# ETHCAT register map
Registers from a debugger description file.
Registers are 8-bit, read-only, no defined reset value unless marked. A register's access mark holds for its fields unless they carry their own. Addresses are absolute; registers are grouped by the start of their names; lines under a group give offsets from that group; [hi:lo] are bit positions; {n}, {i} and the like mark numbered series; 'fields as' and 'values as' point back to an identical list; <NAME> marks a mode.

## SFR
0x44010000 TYPE
0x44010001 REVISION
  [7:0] REV
0x44010002 BUILD 16-bit
0x44010004 FMMU_NUM
  [7:0] NUMFMMU
0x44010006 RAM_SIZE
  [7:0] RAMSIZE
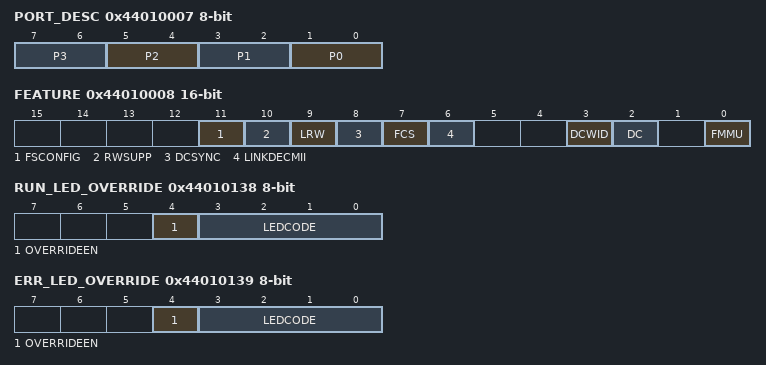
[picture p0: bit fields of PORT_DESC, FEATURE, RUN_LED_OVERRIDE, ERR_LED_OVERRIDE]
0x44010007 PORT_DESC
  [2n+1:2n] P{n} (n=0..3)
0x44010008 FEATURE 16-bit
  [11] FSCONFIG, [10] RWSUPP, [9] LRW, [8] DCSYNC, [7] FCS, [6] LINKDECMII, [3] DCWID, [2] DC, [0] FMMU
0x44010108 PHYSICAL_RW_OFFSET 16-bit
  [15:0] RWOFFSET
0x44010138 RUN_LED_OVERRIDE access not given
  [4] OVERRIDEEN, [3:0] LEDCODE
0x44010139 ERR_LED_OVERRIDE access not given
  [4] OVERRIDEEN, [3:0] LEDCODE
0x44010152 EXT_PDI_CONFIG 16-bit
  [1:0] DATABUSWID
0x44010400 WD_DIVIDE 16-bit
  [15:0] WDDIV
0x44010440 WDS_DATA 16-bit
  [0] WDSTAPD
0x44010E00 PRODUCT_ID 64-bit
  [63:0] PROID
0x44010E08 VENDOR_ID 64-bit
  [31:0] VENDORID

## SYNC
0x44010005 SYNC_MANAGER
  [7:0] NUMSYNC
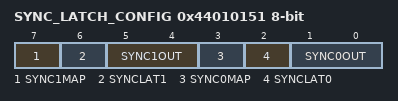
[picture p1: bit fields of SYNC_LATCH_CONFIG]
0x44010151 SYNC_LATCH_CONFIG
  [7] SYNC1MAP, [6] SYNCLAT1, [5:4] SYNC1OUT, [3] SYNC0MAP, [2] SYNCLAT0, [1:0] SYNC0OUT

## STATION
0x44010010 STATION_ADR 16-bit access not given
  [15:0] NODADDR
0x44010012 STATION_ALIAS 16-bit
  [15:0] NODALIADDR

## WR
0x44010020 WR_REG_ENABLE
  [0] ENABLE
0x44010021 WR_REG_PROTECT
  [0] PROTECT

## ESC
0x44010030 ESC_WR_ENABLE
  [0] ENABLE
0x44010031 ESC_WR_PROTECT
  [0] PROTECT
0x44010040 ESC_RESET_ECAT
  [7:0] RESET_ECAT
0x44010041 ESC_RESET_PDI access not given
  [7:0] RESET_PDI
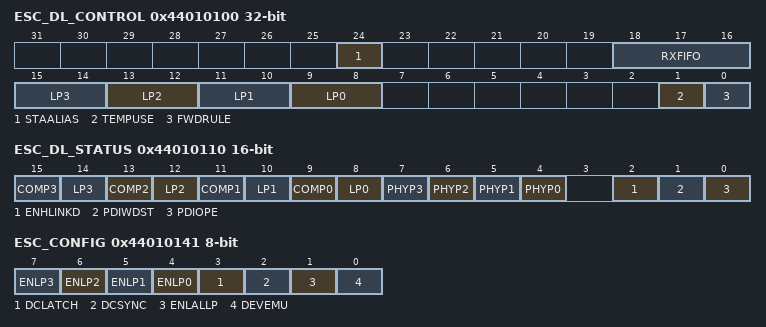
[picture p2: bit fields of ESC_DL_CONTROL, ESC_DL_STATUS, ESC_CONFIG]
0x44010100 ESC_DL_CONTROL 32-bit
  [24] STAALIAS, [18:16] RXFIFO, [2n+9:2n+8] LP{n} (n=0..3), [1] TEMPUSE, [0] FWDRULE
0x44010110 ESC_DL_STATUS 16-bit
  [2n+9] COMP{n} (n=0..3), [2n+8] LP{n} (n=0..3), [n+4] PHYP{n} (n=0..3), [2] ENHLINKD, [1] PDIWDST, [0] PDIOPE
0x44010141 ESC_CONFIG
  [n+4] ENLP{n} (n=0..3), [3] DCLATCH, [2] DCSYNC, [1] ENLALLP, [0] DEVEMU

## AL
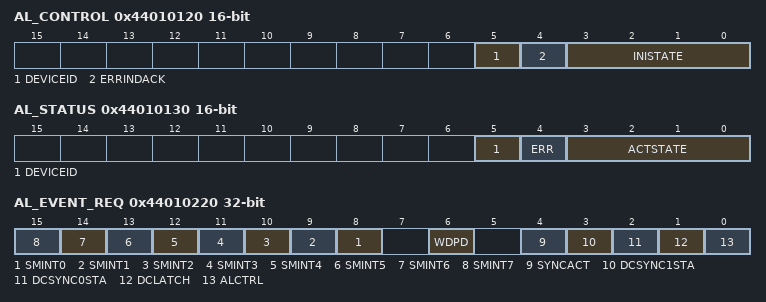
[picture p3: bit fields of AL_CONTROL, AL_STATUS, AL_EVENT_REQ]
0x44010120 AL_CONTROL 16-bit
  [5] DEVICEID, [4] ERRINDACK, [3:0] INISTATE
0x44010130 AL_STATUS 16-bit access not given
  [5] DEVICEID, [4] ERR, [3:0] ACTSTATE
0x44010134 AL_STATUS_CODE 16-bit access not given
  [15:0] STATUSCODE
0x44010204 AL_EVENT_MASK 32-bit access not given
  [31:0] ALEVMASK
0x44010220 AL_EVENT_REQ 32-bit
  [n+8] SMINT{n} (n=0..7), [6] WDPD, [4] SYNCACT, [3] DCSYNC1STA, [2] DCSYNC0STA, [1] DCLATCH, [0] ALCTRL

## PDI
0x44010140 PDI_CONTROL
  [7:0] PDI
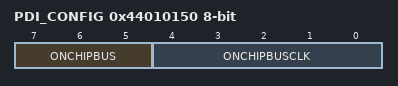
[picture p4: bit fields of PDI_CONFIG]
0x44010150 PDI_CONFIG
  [7:5] ONCHIPBUS, [4:0] ONCHIPBUSCLK
0x4401030D PDI_ERR_COUNT
  [7:0] PDIERRCNT

## ECAT
0x44010200 ECAT_EVENT_MASK 16-bit
  [15:0] ECATEVMASK
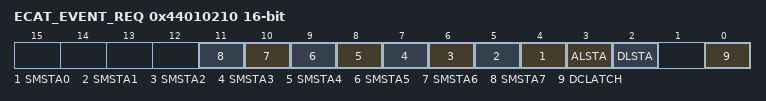
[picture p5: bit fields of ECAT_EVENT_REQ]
0x44010210 ECAT_EVENT_REQ 16-bit
  [n+4] SMSTA{n} (n=0..7), [3] ALSTA, [2] DLSTA, [0] DCLATCH
0x4401030C ECAT_PROC_ERR_COUNT
  [7:0] EPUERRCNT

## RX
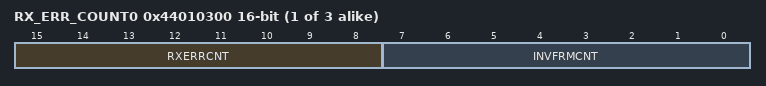
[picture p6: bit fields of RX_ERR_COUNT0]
{0x44010300+2i} RX_ERR_COUNT{i} 16-bit (i=0..2)
  [15:8] RXERRCNT, [7:0] INVFRMCNT

## FWD
{0x44010308+i} FWD_RX_ERR_COUNT{i} (i=0..2)
  [7:0] FWDERRCNT

## LOST
{0x44010310+i} LOST_LINK_COUNT{i} (i=0..2)
  [7:0] LOSTLINKCNT

## WDT
0x44010410 WDT_PDI 16-bit
  [15:0] WDTIMPDI
0x44010420 WDT_DATA 16-bit
  [15:0] WDTIMPD
